# CH564 register map
Vendor: WCH Ltd.; File version: 1.0
Registers are 8-bit, read-write, reset 0x0 unless marked. A register's access mark holds for its fields unless they carry their own. Offsets are from the block's base; [hi:lo] are bit positions; {n}, {i} and the like mark numbered series.

## USBHS_DEV — USB register
Base 0x40404000
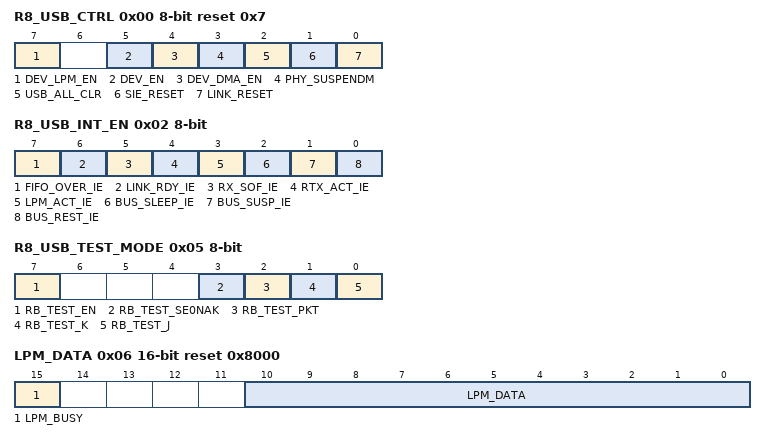
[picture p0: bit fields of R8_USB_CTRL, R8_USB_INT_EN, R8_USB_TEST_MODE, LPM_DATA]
0x00 R8_USB_CTRL reset 0x7 — USB base control register
  [7] DEV_LPM_EN — LPM enable
  [5] DEV_EN — USB device enabled
  [4] DEV_DMA_EN — DMA transfer enabled
  [3] PHY_SUSPENDM — USB PHY suspend
  [2] USB_ALL_CLR — clear all interrupt flags
  [1] SIE_RESET — USB protocol processor reset
  [0] LINK_RESET — LINK layer reset,highly effective
0x01 R8_USB_BASE_MODE — USB mode control register
  [1:0] EXP_SPD — The desired speed mode of the device
0x02 R8_USB_INT_EN — USB interrupt enable register
  [7] FIFO_OVER_IE — USB Overflow interrupt enable
  [6] LINK_RDY_IE — USB connection interrupt enable
  [5] RX_SOF_IE — Receive SOF packet interrupt enable
  [4] RTX_ACT_IE — USB transfer end interrupt enabled
  [3] LPM_ACT_IE — LMP transfer end interrupt enabled
  [2] BUS_SLEEP_IE — USB bus sleep interrupt enabled
  [1] BUS_SUSP_IE — USB bus pause interrupt enabled
  [0] BUS_REST_IE — USB bus reset interrupt enabled
0x03 R8_USB_DEV_AD — USB device address
  [6:0] RB_MASK_USB_ADDR — bit mask for USB device address
0x04 R8_USB_WAKE_CTRL 16-bit ro — USB remote wake up register
  [0] RB_RMT_WAKE — remote wake up
0x05 R8_USB_TEST_MODE — USB test mode register
  [7] RB_TEST_EN — test mode enable
  [3] RB_TEST_SE0NAK — test mode,output SEO
  [2] RB_TEST_PKT — test mode,output a packet
  [1] RB_TEST_K — test mode,output K
  [0] RB_TEST_J — test mode,output J
0x06 LPM_DATA 16-bit access per field reset 0x8000 — USB power management register
  [15] LPM_BUSY rw — power management busy
  [10:0] LPM_DATA ro — power management data
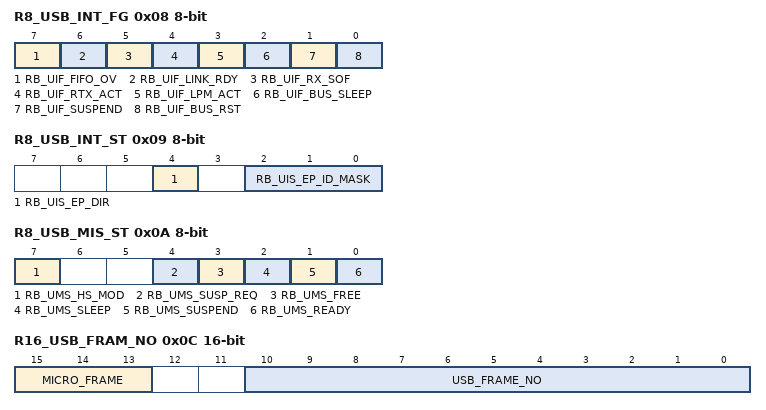
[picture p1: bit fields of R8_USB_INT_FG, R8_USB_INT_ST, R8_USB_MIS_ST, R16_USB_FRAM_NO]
0x08 R8_USB_INT_FG access per field — USB interrupt flag register
  [7] RB_UIF_FIFO_OV rw — USB Overflow interrupt flag
  [6] RB_UIF_LINK_RDY rw — USB connection interrupt flag
  [5] RB_UIF_RX_SOF rw — Receive SOF packet interrupt flag
  [4] RB_UIF_RTX_ACT ro — USB transmission end interrupt flag
  [3] RB_UIF_LPM_ACT rw — LPM transmission end interrupt flag
  [2] RB_UIF_BUS_SLEEP rw — USB bus sleep interrupt flag
  [1] RB_UIF_SUSPEND rw — USB bus suspend interrupt flag
  [0] RB_UIF_BUS_RST rw — USB bus reset interrupt flag
0x09 R8_USB_INT_ST ro — USB interrupt status
  [4] RB_UIS_EP_DIR — Endpoint data transmission direction
  [2:0] RB_UIS_EP_ID_MASK — The endpoint number at which the data transfer occurs
0x0A R8_USB_MIS_ST ro — USB miscellaneous status
  [7] RB_UMS_HS_MOD — whether the host is high-speed
  [4] RB_UMS_SUSP_REQ — USB suspends the request
  [3] RB_UMS_FREE — USB free status
  [2] RB_UMS_SLEEP — USB sleep status
  [1] RB_UMS_SUSPEND — USB suspend status
  [0] RB_UMS_READY — USB connection status
0x0C R16_USB_FRAM_NO 16-bit ro — USB frame number
  [15:13] MICRO_FRAME — Received micro frame number
  [10:0] USB_FRAME_NO — Received frame number
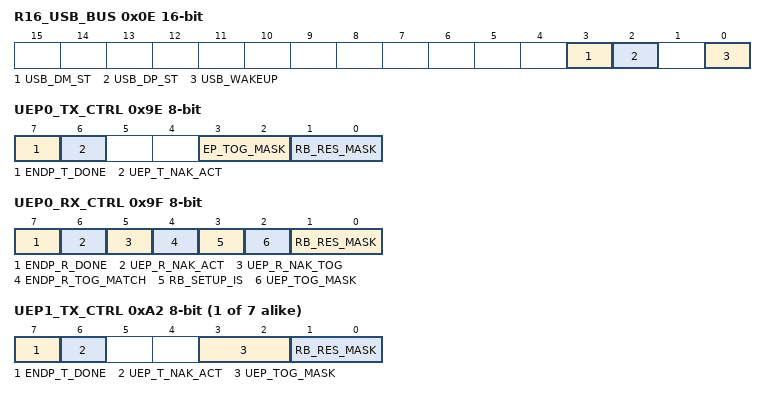
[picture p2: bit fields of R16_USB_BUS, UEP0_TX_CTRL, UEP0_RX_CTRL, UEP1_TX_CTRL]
0x0E R16_USB_BUS 16-bit ro — USB bus
  [3] USB_DM_ST — UDM status
  [2] USB_DP_ST — UDP status
  [0] USB_WAKEUP
0x10 UEP_TX_EN 16-bit — USB endpoint sends the enable register
  [15:0] UEP_TX_EN — Endpoint 0 to 15 sends enable
0x12 UEP_RX_EN 16-bit — USB endpoint receive the enable registers
  [15:0] UEP_RX_EN — Endpoint 0 to 15 receive enable
0x14 UEP_T_TOG_AUTO 16-bit — USB endpoint sends the auto-filp enable register
  [7:0] UEP_T_TOG_AUTO — 0 to 7 endpoint synchronization triggers bit auto-filp enable
0x16 UEP_R_TOG_AUTO 16-bit — USB endpoint receive the auto-filp enable register
  [7:0] UEP_R_TOG_AUTO — 0 to 7 endpoint synchronization triggers bit auto-filp enable
0x18 UEP_T_BURST — USB endpoint sends a burst register
  [7:0] UEP_T_BURST_EN — 0 to 7 endpoint send burst enable
0x19 UEP_T_BURST_MODE — USB endpoint send the mode register
  [7:0] UEP_T_BURST_EN — 0 to 7 endpoint send the mode enable
0x1A UEP_R_BURST — USB endpoint receives the burst register
  [7:0] UEP_R_BURST_EN — 0 to 7 endpoint receive burst enable
0x1B UEP_R_RES_MODE — USB endpoint reply mode register
  [7:0] UEP_R_RES_MODE — 0 to 7 endpoint reply mode
0x1C UEP_AF_MODE 32-bit — USB endpoint muitiplexing register
  [7:1] EP_T_AF — 1 to 7 endpoint muitiplexing enables
0x20 UEP0_DMA 32-bit — The start address register of the endpoint 0 buffer
  [16:0] UEP0_DMA — The start address of the endpoint 0 buffer
{0x20+4i} UEP{i}_RX_DMA 32-bit (i=1..7) — endpoint {i} receives the start address register of the buffer
  [16:0] UEP{i}_RX_DMA — endpoint receives the start address register of the buffer
{0x3C+4i} UEP{i}_TX_DMA 32-bit (i=1..7) — endpoint {i} sends the start address register of the buffer
  [16:0] UEP{i}_TX_DMA — endpoint sends the start address register of the buffer
{0x5C+4i} UEP{i}_MAX_LEN 32-bit (i=0..7) — endpoint {i} max length packet register
  [6:0] UEP{i}_MAX_LEN — endpoint {i} max acceptable offset length
0x7C UEP0_RX_LEN 16-bit — endpoint 0 acceptable length
  [6:0] UEP0_RX_LEN — endpoint 0 acceptable data length
{0x7C+4i} UEP{i}_RX_LEN 16-bit (i=1..7) — endpoint {i} receives the lenth register in a single pass
  [15:0] UEP{i}_RX_LEN — the length of data received by endpoint {i} in a single pass
{0x7E+4i} UEP{i}_R_SIZE 16-bit (i=1..7) — the length register of the total received data at endpoint {i}
  [15:0] UEP{i}_R_SIZE — the length of the total received data at endpoint {i}
0x9C UEP0_T_LEN 16-bit — endpoint 0 send the length
  [6:0] UEP0_T_LEN
0x9E UEP0_TX_CTRL — endpoint 0 send control register
  [7] ENDP_T_DONE — endpoint 0 sends the end of NAK flag
  [6] UEP_T_NAK_ACT — endpoint 0 sends the end flag
  [3:2] EP_TOG_MASK — endpoint 0 synchronous trigger bit for the sender to prepare
  [1:0] RB_RES_MASK — endpoint 0 control of the send response to IN transactions
0x9F UEP0_RX_CTRL access per field — endpoint 0 send control register
  [7] ENDP_R_DONE rw — endpoint 0 receives the end flag
  [6] UEP_R_NAK_ACT rw — endpoint 0 receives the end of NAK flag
  [5] UEP_R_NAK_TOG ro — endpoint 0 for the received return NAK,packet type
  [4] ENDP_R_TOG_MATCH ro — received synchronization trigger bit matches the desired synchronization trigger bit state
  [3] RB_SETUP_IS ro — whether endpoint 0 receives a SETUP transaction
  [2] UEP_TOG_MASK rw — the reception of endpoint 0 expects a synchronous trigger bit
  [1:0] RB_RES_MASK rw — endpoint 0 has control over the received response
0xA0 UEP1_T_LEN 16-bit — endpoint 1 send the length register
  [15:0] UEP1_T_LEN — endpoint 1 send the length
{0x9E+4i} UEP{i}_TX_CTRL (i=1..7) — endpoint {i} send control register
  [7] ENDP_T_DONE — endpoint {i} sends the end of NAK flag
  [6] UEP_T_NAK_ACT — endpoint {i} sends the end flag
  [3:2] UEP_TOG_MASK — endpoint {i} synchronous trigger bit for the sender to prepare
  [1:0] RB_RES_MASK — endpoint {i} control of the send response to IN transactions
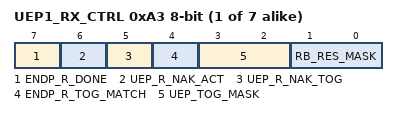
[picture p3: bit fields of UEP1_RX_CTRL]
{0x9F+4i} UEP{i}_RX_CTRL access per field (i=1..7) — endpoint {i} receive control
  [7] ENDP_R_DONE rw — endpoint {i} receives the end flag
  [6] UEP_R_NAK_ACT rw — endpoint {i} receives the end of NAK flag
  [5] UEP_R_NAK_TOG ro — endpoint {i} for the received return NAK,packet type
  [4] ENDP_R_TOG_MATCH ro — received synchronization trigger bit matches the desired synchronization trigger bit state
  [3:2] UEP_TOG_MASK rw — the reception of endpoint {i} expects a synchronous trigger bit
  [1:0] RB_RES_MASK rw — endpoint {i} has control over the received response
{0x9C+4i} UEP{i}_T_LEN 16-bit (i=2..7) — endpoint {i} send the length register
  [15:0] UEP_TX_LEN — endpoint {i} send the length
0xBC UEP_T_ISO 16-bit — usb endpoint sends a synchronous mode enable register
  [7:1] UEP_T_ISO — upload endpoint(IN) synchronization mode enabled
0xBE UEP_R_ISO 16-bit — usb endpoint receives a synchronous mode enable register
  [7:1] UEP_R_ISO — down endpoint(OUT) synchronization mode enabled
